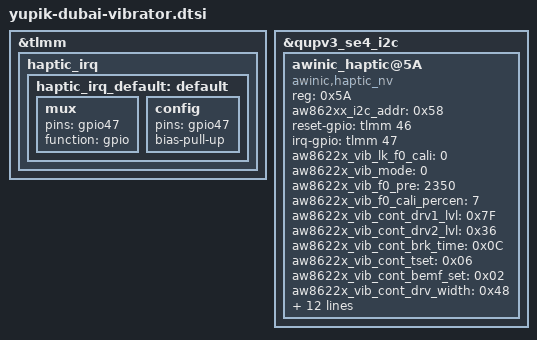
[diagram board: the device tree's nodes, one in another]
/* AWINIC AW862XX Haptic */
&tlmm{
	haptic_irq {
		haptic_irq_default: default {
			mux {
				pins = "gpio47";
				function = "gpio";
			};
			config {
				pins = "gpio47";
				bias-pull-up;
			};
		};
	};
};

&qupv3_se4_i2c {
	status = "ok";
	awinic_haptic@5A{
		compatible = "awinic,haptic_nv";
		reg = < 0x5A >;
		aw862xx_i2c_addr = < 0x58 >;
		reset-gpio = <&tlmm 46 0>;
		irq-gpio = <&tlmm 47 0>;
		aw8622x_vib_lk_f0_cali = < 0 >;
		aw8622x_vib_mode = < 0 >; /* mode: RAM mode->0; CONT mode->1 */
		aw8622x_vib_f0_pre = < 2350 >;
		aw8622x_vib_f0_cali_percen = < 7 >;
		aw8622x_vib_cont_drv1_lvl = < 0x7F >;
		aw8622x_vib_cont_drv2_lvl = < 0x36 >;
		aw8622x_vib_cont_brk_time = < 0x0C >;
		aw8622x_vib_cont_tset = < 0x06 >;
		aw8622x_vib_cont_bemf_set = < 0x02 >;
		aw8622x_vib_cont_drv_width = < 0x48 >;
		aw8622x_vib_cont_wait_num = < 0x06 >;
		aw8622x_vib_cont_brk_gain = < 0x0A >;
		aw8622x_vib_cont_drv1_time = < 0x04 >;
		aw8622x_vib_cont_drv2_time = < 0x14 >;
		aw8622x_vib_cont_track_margin = < 0x12 >;
		aw8622x_vib_sine_array = < 0x05 0xB2 0xFF 0xEF >; /* SIN_H SIN_L COS_H COS_L*/
		aw8622x_vib_d2s_gain = < 0x07 >;
		aw8622x_vib_prctmode = < 0x2D 0x3E 0x3F >;
		aw8622x_vib_trig_config = < 0 0 0 1 0 2 0
					    0 0 0 1 0 2 0
					    0 0 0 1 0 2 0 >;
		aw8622x_vib_duration_time = < 30 65 105 >;
		pinctrl-names = "default";
		pinctrl-0 = <&haptic_irq_default>;
		status = "okay";
	};
};
